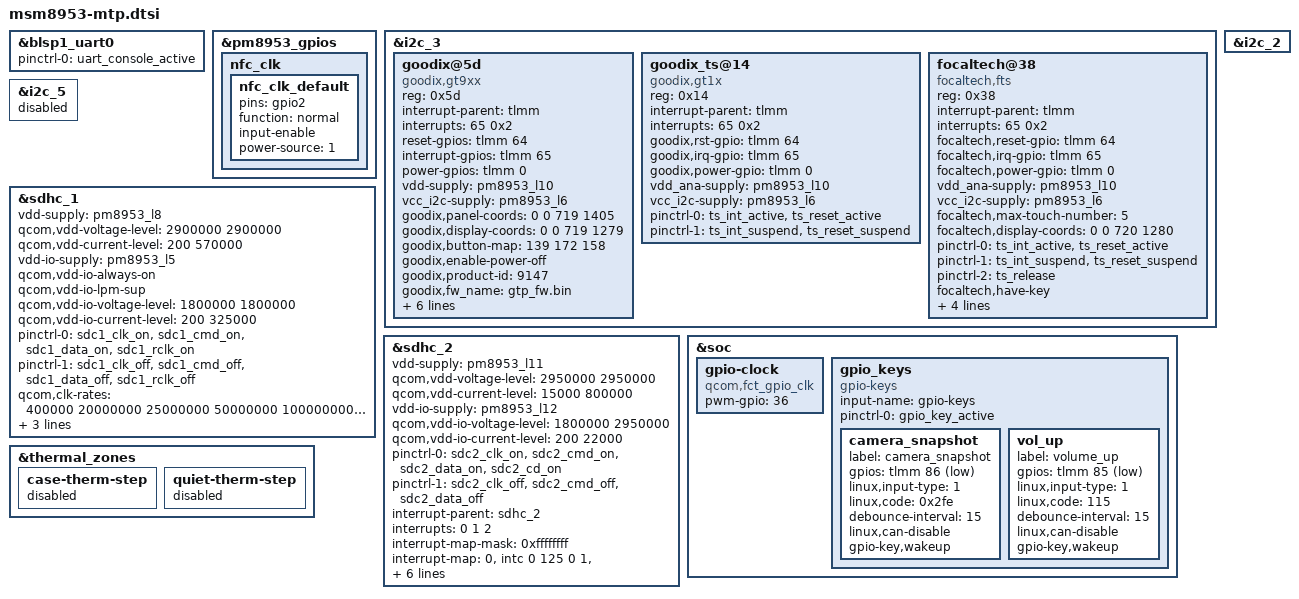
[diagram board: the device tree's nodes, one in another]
/*
 * Copyright (c) 2015-2018, The Linux Foundation. All rights reserved.
 *
 * This program is free software; you can redistribute it and/or modify
 * it under the terms of the GNU General Public License version 2 and
 * only version 2 as published by the Free Software Foundation.
 *
 * This program is distributed in the hope that it will be useful,
 * but WITHOUT ANY WARRANTY; without even the implied warranty of
 * MERCHANTABILITY or FITNESS FOR A PARTICULAR PURPOSE.  See the
 * GNU General Public License for more details.
 */

#include <dt-bindings/gpio/gpio.h>
#include <dt-bindings/clock/msm-clocks-8953.h>
#include "msm8953-camera-sensor-mtp.dtsi"

&blsp1_uart0 {
	status = "ok";
	pinctrl-names = "default";
	pinctrl-0 = <&uart_console_active>;
};

&pm8953_gpios {
	nfc_clk {
		nfc_clk_default: nfc_clk_default {
			pins = "gpio2";
			function = "normal";
			input-enable;
			power-source = <1>;
		};
	};
};

//rid-> add i2c3 for tp0
&i2c_3 {  /* BLSP1 QUP3 */
    status = "ok";
    goodix@5d {
        compatible = "goodix,gt9xx";
        reg = <0x5d>;
        interrupt-parent = <&tlmm>;
        interrupts = <65 0x2>;
        reset-gpios = <&tlmm 64 0x0>;
        interrupt-gpios = <&tlmm 65 0x2008>;
        power-gpios = <&tlmm 0 0x0>;
        vdd-supply = <&pm8953_l10>;
        vcc_i2c-supply = <&pm8953_l6>;
        goodix,panel-coords = <0 0 719 1405>;
        goodix,display-coords = <0 0 719 1279>;
        goodix,button-map= <139 172 158>;
        goodix,enable-power-off;
        goodix,product-id = "9147";
        goodix,fw_name = "gtp_fw.bin";
        pinctrl-names = "pmx_ts_active","pmx_ts_suspend";
        pinctrl-0 = <&ts_int_active &ts_reset_active>;
        pinctrl-1 = <&ts_int_suspend &ts_reset_suspend>;
        goodix,cfg-data0 = [
        44 DA 02 05 05 05 35 C1 01 09
        28 08 48 35 03 05 00 00 FF 7F
        10 50 85 14 17 1A 14 92 00 0A
        31 2F D3 07 03 00 00 A2 33 1D
        00 01 00 00 00 1E 00 09 10 00
        2A 1E 50 94 C5 02 00 0E 00 04
        B1 21 00 96 28 00 7F 31 00 6F
        3B 00 60 48 00 60 10 30 48 00
        F0 4A 3A FF EF 27 00 00 00 00
        00 01 1C 19 17 0F 01 00 01 0F
        0F 03 04 10 42 8F 0F 19 00 00
        46 37 08 0A 0C 0E 10 12 14 16
        18 1A 00 00 00 00 00 00 00 00
        00 00 00 00 00 00 00 00 00 00
        00 00 08 20 0A 1F 0C 1E 0E 1D
        22 05 24 04 28 00 29 02 2A 06
        00 00 00 00 00 00 00 00 00 00
        00 FF FF FF FF FF FF FF FF AF
        FF FF FF FF 87 01
        ];
        goodix,have-touch-key;
        goodix,driver-send-cfg;
    };

    goodix_ts@14 {
        compatible = "goodix,gt1x";
        reg = <0x14>;
        interrupt-parent = <&tlmm>;
        interrupts = <65 0x2>;
        goodix,rst-gpio  = <&tlmm 64 0x0>;
        goodix,irq-gpio = <&tlmm 65 0x2008>;
        goodix,power-gpio = <&tlmm 0 0x0>;
        vdd_ana-supply = <&pm8953_l10>;
        vcc_i2c-supply  = <&pm8953_l6>;
        pinctrl-names = "pmx_ts_active","pmx_ts_suspend";
        pinctrl-0 = <&ts_int_active &ts_reset_active>;
        pinctrl-1 = <&ts_int_suspend &ts_reset_suspend>;
    };

	focaltech@38{
		compatible = "focaltech,fts";
		reg = <0x38>;
		interrupt-parent = <&tlmm>;
		interrupts = <65 0x2>;
		focaltech,reset-gpio = <&tlmm 64 0x0>;
		focaltech,irq-gpio = <&tlmm 65 0x02008>;
		focaltech,power-gpio = <&tlmm 0 0x0>;
		vdd_ana-supply = <&pm8953_l10>;
		vcc_i2c-supply  = <&pm8953_l6>;
		focaltech,max-touch-number = <5>;
		focaltech,display-coords =  <0 0 720 1280>;
		pinctrl-names = "pmx_ts_active","pmx_ts_suspend","pmx_ts_release";
		pinctrl-0 = <&ts_int_active &ts_reset_active>;
		pinctrl-1 = <&ts_int_suspend &ts_reset_suspend>;
		pinctrl-2 = <&ts_release>;
		focaltech,have-key;
		focaltech,key-number = <3>;
		focaltech,keys = <139 172 158>;
		focaltech,key-y-coords = <1340 1340 1340>;
		focaltech,key-x-coords = <150 330 660>;
	};
};

//raynor-> add second tp
&i2c_2 {
/*
    goodix@5d {
        compatible = "goodix,gt9xx_second";
        reg = <0x5d>;
        interrupt-parent = <&tlmm>;
        interrupts = <9 0x2>;
        reset-gpios = <&tlmm 8 0x0>;
        interrupt-gpios = <&tlmm 9 0x2008>;
        power-gpios = <&tlmm 0 0x0>;
        vdd-supply = <&pm8953_l10>;
        vcc_i2c-supply = <&pm8953_l6>;
        goodix,panel-coords = <0 0 719 1405>;
        goodix,display-coords = <0 0 719 1279>;
        goodix,button-map= <139 172 158>;
        goodix,enable-power-off;
        goodix,product-id = "9147";
        goodix,fw_name = "gtp_fw.bin";
        pinctrl-names = "pmx_ts_sec_active","pmx_ts_sec_suspend";
        pinctrl-0 = <&ts_sec_int_active &ts_sec_reset_active>;
        pinctrl-1 = <&ts_sec_int_suspend &ts_sec_reset_suspend>;
        goodix,cfg-data0 = [
        44 DA 02 05 05 05 35 C1 01 09
        28 08 48 35 03 05 00 00 FF 7F
        10 50 85 14 17 1A 14 92 00 0A
        31 2F D3 07 03 00 00 A2 33 1D
        00 01 00 00 00 1E 00 09 10 00
        2A 1E 50 94 C5 02 00 0E 00 04
        B1 21 00 96 28 00 7F 31 00 6F
        3B 00 60 48 00 60 10 30 48 00
        F0 4A 3A FF EF 27 00 00 00 00
        00 01 1C 19 17 0F 01 00 01 0F
        0F 03 04 10 42 8F 0F 19 00 00
        46 37 08 0A 0C 0E 10 12 14 16
        18 1A 00 00 00 00 00 00 00 00
        00 00 00 00 00 00 00 00 00 00
        00 00 08 20 0A 1F 0C 1E 0E 1D
        22 05 24 04 28 00 29 02 2A 06
        00 00 00 00 00 00 00 00 00 00
        00 FF FF FF FF FF FF FF FF AF
        FF FF FF FF 87 01
        ];
        goodix,have-touch-key;
        goodix,driver-send-cfg;
    };

    goodix_ts@14 {
        compatible = "goodix,gt1x_second";
        reg = <0x14>;
        interrupt-parent = <&tlmm>;
        interrupts = <9 0x2>;
        goodix,rst-gpio  = <&tlmm 8 0x0>;
        goodix,irq-gpio = <&tlmm 9 0x2008>;
        goodix,power-gpio = <&tlmm 0 0x0>;
        vdd_ana-supply = <&pm8953_l10>;
        vcc_i2c-supply  = <&pm8953_l6>;
        pinctrl-names = "pmx_ts_sec_active","pmx_ts_sec_suspend";
        pinctrl-0 = <&ts_sec_int_active &ts_sec_reset_active>;
        pinctrl-1 = <&ts_sec_int_suspend &ts_sec_reset_suspend>;
    };

    focaltech@38 {
	compatible = "focaltech,fts_second";
	reg = <0x38>;
	interrupt-parent = <&tlmm>;
	interrupts = <9 0x2>;
	focaltech,reset-gpio = <&tlmm 8 0x0>;
	focaltech,irq-gpio = <&tlmm 9 0x02008>;
	focaltech,power-gpio = <&tlmm 0 0x0>;
	vdd_ana-supply = <&pm8953_l10>;
	vcc_i2c-supply  = <&pm8953_l6>;
	focaltech,max-touch-number = <5>;
	focaltech,display-coords =  <0 0 720 1280>;
	pinctrl-names = "pmx_ts_sec_active","pmx_ts_sec_suspend","pmx_ts_sec_release";
	pinctrl-0 = <&ts_sec_int_active &ts_sec_reset_active>;
	pinctrl-1 = <&ts_sec_int_suspend &ts_sec_reset_suspend>;
	pinctrl-2 = <&ts_sec_release>;
	focaltech,have-key;
	focaltech,key-number = <3>;
	focaltech,keys = <139 172 158>;
	focaltech,key-y-coords = <1340 1340 1340>;
	focaltech,key-x-coords = <150 330 660>;
    };
*/
/*
    nq@28 {
	compatible = "qcom,nq-nci";
	reg = <0x28>;
	qcom,nq-irq = <&tlmm 90 0x00>;
	qcom,nq-ven = <&tlmm 9 0x00>;
	qcom,nq-firm = <&tlmm 8 0x00>;
	qcom,nq-clkreq = <&pm8953_gpios 2 0x00>;
	qcom,nq-esepwr = <&tlmm 141 0x00>;
	interrupt-parent = <&tlmm>;
	qcom,clk-src = "BBCLK2";
	interrupts = <90 0>;
	interrupt-names = "nfc_irq";
	pinctrl-names = "nfc_active", "nfc_suspend";
	pinctrl-0 = <&nfc_int_active &nfc_disable_active &nfc_clk_default>;
	pinctrl-1 = <&nfc_int_suspend &nfc_disable_suspend>;
	clocks = <&clock_gcc clk_bb_clk2_pin>;
	clock-names = "ref_clk";
    };
*/
};

&i2c_5 { /* BLSP2 QUP1 (NFC) */
	status = "disabled";
};

&sdhc_1 {
	/* device core power supply */
	vdd-supply = <&pm8953_l8>;
	qcom,vdd-voltage-level = <2900000 2900000>;
	qcom,vdd-current-level = <200 570000>;

	/* device communication power supply */
	vdd-io-supply = <&pm8953_l5>;
	qcom,vdd-io-always-on;
	qcom,vdd-io-lpm-sup;
	qcom,vdd-io-voltage-level = <1800000 1800000>;
	qcom,vdd-io-current-level = <200 325000>;

	pinctrl-names = "active", "sleep";
	pinctrl-0 = <&sdc1_clk_on &sdc1_cmd_on &sdc1_data_on  &sdc1_rclk_on>;
	pinctrl-1 = <&sdc1_clk_off &sdc1_cmd_off &sdc1_data_off &sdc1_rclk_off>;

	qcom,clk-rates = <400000 20000000 25000000 50000000 100000000 192000000
								384000000>;
	qcom,nonremovable;
	qcom,bus-speed-mode = "HS400_1p8v", "HS200_1p8v", "DDR_1p8v";

	status = "ok";
};

&sdhc_2 {
	/* device core power supply */
	vdd-supply = <&pm8953_l11>;
	qcom,vdd-voltage-level = <2950000 2950000>;
	qcom,vdd-current-level = <15000 800000>;

	/* device communication power supply */
	vdd-io-supply = <&pm8953_l12>;
	qcom,vdd-io-voltage-level = <1800000 2950000>;
	qcom,vdd-io-current-level = <200 22000>;

	pinctrl-names = "active", "sleep";
	pinctrl-0 = <&sdc2_clk_on &sdc2_cmd_on &sdc2_data_on &sdc2_cd_on>;
	pinctrl-1 = <&sdc2_clk_off &sdc2_cmd_off &sdc2_data_off>;

	#address-cells = <0>;
	interrupt-parent = <&sdhc_2>;
	interrupts = <0 1 2>;
	#interrupt-cells = <1>;
	interrupt-map-mask = <0xffffffff>;
	interrupt-map = <0 &intc 0 125 0
		1 &intc 0 221 0
		2 &tlmm 133 0>;
	interrupt-names = "hc_irq", "pwr_irq", "status_irq";
	cd-gpios = <&tlmm 133 0x1>;

	qcom,clk-rates = <400000 20000000 25000000 50000000 100000000
								200000000>;
	qcom,bus-speed-mode = "SDR12", "SDR25", "SDR50", "DDR50", "SDR104";

	status = "ok";
};

&soc {
	gpio-clock {
               compatible = "qcom,fct_gpio_clk";
               pwm-gpio = <36>;
       };
	gpio_keys {
		compatible = "gpio-keys";
		input-name = "gpio-keys";
		pinctrl-names = "default";
		pinctrl-0 = <&gpio_key_active>;
		camera_snapshot {
			label = "camera_snapshot";
			gpios = <&tlmm 86 0x1>;
			linux,input-type = <1>;
			linux,code = <0x2fe>;
			debounce-interval = <15>;
			linux,can-disable;
			gpio-key,wakeup;
		};

		vol_up {
			label = "volume_up";
			gpios = <&tlmm 85 0x1>;
			linux,input-type = <1>;
			linux,code = <115>;
			debounce-interval = <15>;
			linux,can-disable;
			gpio-key,wakeup;
		};
	};
};

&thermal_zones {
	case-therm-step {
		status = "disabled";
	};

	quiet-therm-step {
		status = "disabled";
	};
};
